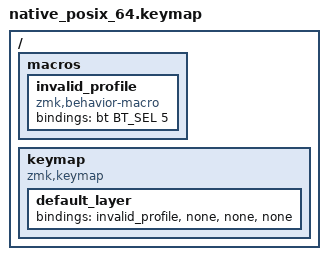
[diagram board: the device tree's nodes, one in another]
/*
 * Copyright (c) 2026 The ZMK Contributors
 *
 * SPDX-License-Identifier: MIT
 */

#include <behaviors.dtsi>
#include <dt-bindings/zmk/bt.h>
#include <dt-bindings/zmk/kscan_mock.h>

/ {
    macros {
        invalid_profile: invalid_profile {
            compatible = "zmk,behavior-macro";
            #binding-cells = <0>;
            bindings = <&bt BT_SEL 5>;
        };
    };

    keymap {
        compatible = "zmk,keymap";

        default_layer {
            bindings = <&invalid_profile &none &none &none>;
        };
    };
};
